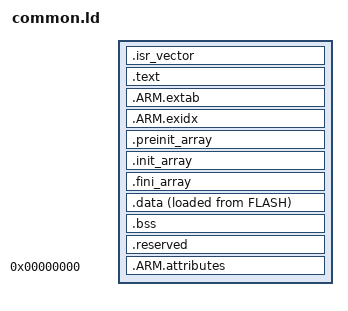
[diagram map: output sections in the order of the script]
ENTRY(Reset_Handler)
_estack = ORIGIN(RAM) + LENGTH(RAM);
SECTIONS
{
  .isr_vector : { . = ALIGN(4); KEEP(*(.isr_vector)) . = ALIGN(4); } > FLASH
  .text : {
    . = ALIGN(4); *(.text*) *(.rodata*) KEEP(*(.init)) KEEP(*(.fini))
    . = ALIGN(4); _etext = .;
  } > FLASH
  .ARM.extab : { *(.ARM.extab*) } > FLASH
  .ARM.exidx : {
    __exidx_start = .; *(.ARM.exidx*) __exidx_end = .;
  } > FLASH
  .preinit_array : {
    PROVIDE_HIDDEN(__preinit_array_start = .);
    KEEP(*(.preinit_array*)) PROVIDE_HIDDEN(__preinit_array_end = .);
  } > FLASH
  .init_array : {
    PROVIDE_HIDDEN(__init_array_start = .);
    KEEP(*(SORT(.init_array.*))) KEEP(*(.init_array))
    PROVIDE_HIDDEN(__init_array_end = .);
  } > FLASH
  .fini_array : {
    PROVIDE_HIDDEN(__fini_array_start = .);
    KEEP(*(SORT(.fini_array.*))) KEEP(*(.fini_array))
    PROVIDE_HIDDEN(__fini_array_end = .);
  } > FLASH
  _sidata = LOADADDR(.data);
  .data : { . = ALIGN(4); _sdata = .; *(.data*) . = ALIGN(4); _edata = .; } > RAM AT > FLASH
  .bss (NOLOAD) : {
    . = ALIGN(4); _sbss = .; __bss_start__ = .;
    *(.bss*) *(COMMON) . = ALIGN(4); _ebss = .; __bss_end__ = .;
  } > RAM
  .reserved (NOLOAD) : {
    . = ALIGN(8); PROVIDE(end = .); PROVIDE(_end = .);
    . += 0x200; . += 0x800; . = ALIGN(8);
  } > RAM
  .ARM.attributes 0 : { *(.ARM.attributes) }
}
ASSERT(_estack >= ADDR(.reserved) + SIZEOF(.reserved), "RAM overflow including reserved heap/stack")
